# XMC4500 register map
Vendor: Infineon; File version: 1.2.0 (Reference Manual v1.2)
CPU: CM4 r2p0, little endian, MPU, FPU, 6 interrupt priority bits
Registers are 32-bit, read-write, reset 0x0 unless marked. A register's access mark holds for its fields unless they carry their own. Offsets are from the block's base; [hi:lo] are bit positions; {n}, {i} and the like mark numbered series; 'fields as' and 'values as' point back to an identical list.

## PPB — Cortex-M4 Private Peripheral Block
Base 0xE000E000
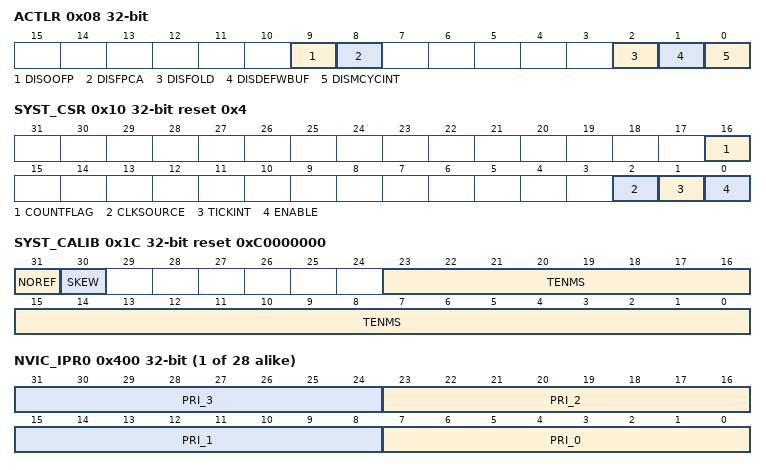
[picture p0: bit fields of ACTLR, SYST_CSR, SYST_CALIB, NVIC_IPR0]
0x08 ACTLR — Auxiliary Control Register
  [9] DISOOFP — Disable out of order FP execution
  [8] DISFPCA — Disable FPCA update
  [2] DISFOLD — Disable IT folding
  [1] DISDEFWBUF — Disable write buffer
  [0] DISMCYCINT — Disable load/store multiple
0x10 SYST_CSR reset 0x4 — SysTick Control and Status Register
  [16] COUNTFLAG — Counter Flag
  [2] CLKSOURCE — Indicates the clock source:
    0=external clock; 1=processor clock
  [1] TICKINT — Tick Interrupt Enable
    0=counting down to zero does not assert the SysTick exception request; 1=counting down to zero to asserts the SysTick exception request
  [0] ENABLE
    0=counter disabled; 1=counter enabled
0x14 SYST_RVR reset not defined — SysTick Reload Value Register
  [23:0] RELOAD — Reload Value
0x18 SYST_CVR reset not defined — SysTick Current Value Register
  [23:0] CURRENT — Current Value
0x1C SYST_CALIB reset 0xC0000000 — SysTick Calibration Value Register r
  [31] NOREF — No Reference Clock
    0=reference clock provided; 1=no reference clock provided
  [30] SKEW — Ten Milliseconds Skewed
    0=TENMS value is exact; 1=TENMS value is inexact, or not given
  [23:0] TENMS — Ten Milliseconds Reload Value
{0x100+4i} NVIC_ISER{i} (i=0..3) — Interrupt Set-enable Register {i}
  [31:0] SETENA — Interrupt set-enable bits
    0=interrupt disabled; 1=interrupt enabled
{0x180+4i} NVIC_ICER{i} (i=0..3) — Interrupt Clear-enable Register {i}
  [31:0] CLRENA — Interrupt clear-enable bits.
    0=interrupt disabled; 1=interrupt enabled
{0x200+4i} NVIC_ISPR{i} (i=0..3) — Interrupt Set-pending Register {i}
  [31:0] SETPEND — Interrupt set-pending bits.
    0=interrupt is not pending; 1=interrupt is pending
{0x280+4i} NVIC_ICPR{i} (i=0..3) — Interrupt Clear-pending Register {i}
  [31:0] CLRPEND — Interrupt set-pending bits.
    0=interrupt is not pending; 1=interrupt is pending
{0x300+4i} NVIC_IABR{i} (i=0..3) — Interrupt Active Bit Register {i}
  [31:0] ACTIVE — Interrupt active flags:
    0=interrupt not active; 1=interrupt active
{0x400+4i} NVIC_IPR{i} (i=0..27) — Interrupt Priority Register {i}
  [8n+7:8n] PRI_{n} (n=0..3) — Priority value {n}
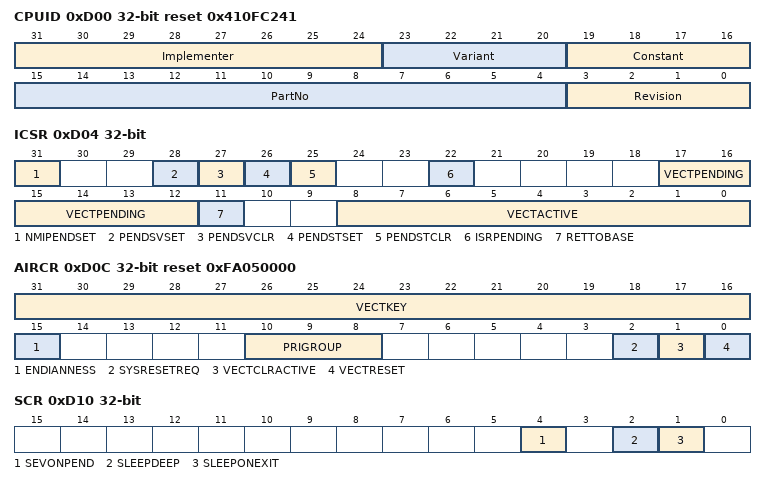
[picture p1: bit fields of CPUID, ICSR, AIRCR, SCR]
0xD00 CPUID ro reset 0x410FC241 — CPUID Base Register
  [31:24] Implementer — Implementer code
    65=ARM
  [23:20] Variant — Variant number
    0=Revision 0
  [19:16] Constant — Reads as 0xF
  [15:4] PartNo — Part number of the processor
    0xC24=Cortex-M4
  [3:0] Revision — Revision number
    1=Patch 1
0xD04 ICSR access per field — Interrupt Control and State Register
  [31] NMIPENDSET rw — NMI set-pending bit: 0b0=no effect, 0b1=changes NMI exception state to pending., 0b0=NMI exception is not pending, 0b1=NMI exception is pending.,
  [28] PENDSVSET rw — PendSV set-pending bit: 0b0=no effect, 0b1=changes PendSV exception state to pending., 0b0=PendSV exception is not pending, 0b1=PendSV exception is pending.,
  [27] PENDSVCLR wo — PendSV clear-pending bit
    0=no effect; 1=removes the pending state from the PendSV exception
  [26] PENDSTSET rw — SysTick exception set-pending bit
    0=no effect; 1=changes SysTick exception state to pending
  [25] PENDSTCLR wo — SysTick exception clear-pending bit
    0=no effect; 1=removes the pending state from the SysTick exception
  [22] ISRPENDING ro — Interrupt pending flag
    0=interrupt not pending; 1=interrupt pending
  [17:12] VECTPENDING ro — Vector Pending
    0=no pending exceptions
  [11] RETTOBASE ro — Return to Base
    0=there are preempted active exceptions to execute; 1=there are no active exceptions, or the currently-executing exception is the only active exception
  [8:0] VECTACTIVE ro — Active exception number
    0=Thread mode
0xD08 VTOR — Vector Table Offset Register
  [31:10] TBLOFF — Vector table base offset field
0xD0C AIRCR access per field reset 0xFA050000 — Application Interrupt and Reset Control Register
  [31:16] VECTKEY rw — Register key
  [15] ENDIANNESS ro — Data endianness bit
    0=Little-endian; 1=Big-endian
  [10:8] PRIGROUP rw — Interrupt priority grouping field
  [2] SYSRESETREQ wo — System reset request
    0=no system reset request; 1=asserts a signal to the outer system that requests a reset
  [1] VECTCLRACTIVE wo — Reserved for Debug use.
  [0] VECTRESET wo — Reserved for Debug use.
0xD10 SCR — System Control Register
  [4] SEVONPEND — Send Event on Pending bit:
    0=only enabled interrupts or events can wakeup the processor, disabled interrupts are excluded; 1=enabled events and all interrupts, including disabled interrupts, can wakeup the processor
  [2] SLEEPDEEP — Sleep or Deep Sleep
    0=sleep; 1=deep sleep
  [1] SLEEPONEXIT
    0=do not sleep when returning to Thread mode; 1=enter sleep, or deep sleep, on return from an ISR
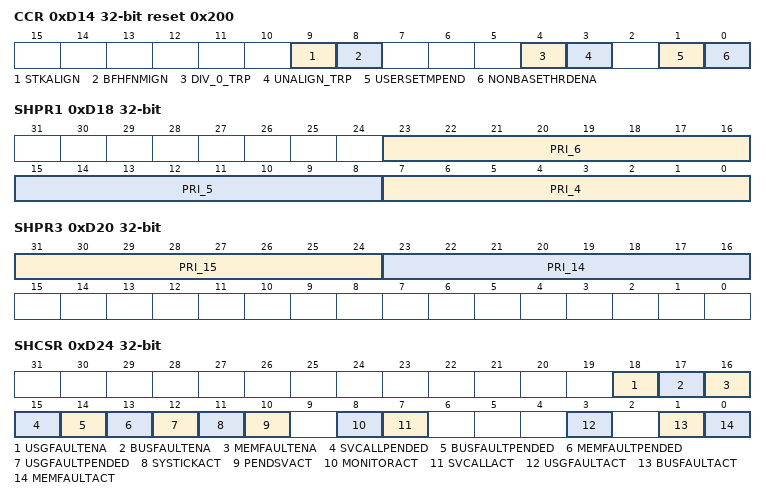
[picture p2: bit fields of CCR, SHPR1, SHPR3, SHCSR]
0xD14 CCR reset 0x200 — Configuration and Control Register
  [9] STKALIGN — Stack Alignment
    0=4-byte aligned; 1=8-byte aligned
  [8] BFHFNMIGN — Bus Fault Hard Fault and NMI Ignore
    0=data bus faults caused by load and store instructions cause a lock-up; 1=handlers running at priority -1 and -2 ignore data bus faults caused by load and store instructions
  [4] DIV_0_TRP — Divide by Zero Trap Enable
    0=do not trap divide by 0; 1=trap divide by 0
  [3] UNALIGN_TRP — Unaligned Access Trap Enable
    0=do not trap unaligned halfword and word accesses; 1=trap unaligned halfword and word accesses
  [1] USERSETMPEND — User Set Pending Enable
    0=disable; 1=enable
  [0] NONBASETHRDENA — Non Base Thread Mode Enable
    0=processor can enter Thread mode only when no exception is active; 1=processor can enter Thread mode from any level under the control of an EXC_RETURN value, see Exception returnException return occurs when the processor is in Handler mode and executes one of the following instructions to load the EXC_RETURN value into the PC:an LDM or POP instruction that loads the PCan LDR instruction with PC as the destinationa BX instruction using any register.EXC_RETURN is the value loaded into the LR on exception entry. The exception mechanism relies on this value to detect when the processor has completed an exception handler. The lowest five bits of this value provide information on the return stack and processor mode. shows the EXC_RETURN values with a description of the exception return behavior. All EXC_RETURN values have bits[31:5] set to one. When this value is loaded into the PC it indicates to the processor that the exception is complete, and the processor initiates the appropriate exception return sequence.Exception return behaviorEXC_RETURN[31:0]Description 0xFFFFFFF1 Return to Handler mode, exception return uses non-floating-point state from the MSP and execution uses MSP after return. 0xFFFFFFF9 Return to Thread mode, exception return uses non-floating-point state from MSP and execution uses MSP after return. 0xFFFFFFFD Return to Thread mode, exception return uses non-floating-point state from the PSP and execution uses PSP after return. 0xFFFFFFE1 Return to Handler mode, exception return uses floating-point-state from MSP and execution uses MSP after return. 0xFFFFFFE9 Return to Thread mode, exception return uses floating-point state from MSP and execution uses MSP after return. 0xFFFFFFED Return to Thread mode, exception return uses floating-point state from PSP and execution uses PSP after return. .
0xD18 SHPR1 — System Handler Priority Register 1
  [23:16] PRI_6 — Priority of system handler 6, UsageFault
  [15:8] PRI_5 — Priority of system handler 5, BusFault
  [7:0] PRI_4 — Priority of system handler 4, MemManage
0xD1C SHPR2 — System Handler Priority Register 2
  [31:24] PRI_11 — Priority of system handler 11, SVCall
0xD20 SHPR3 — System Handler Priority Register 3
  [31:24] PRI_15 — Priority of system handler 15
  [23:16] PRI_14 — Priority of system handler 14
0xD24 SHCSR — System Handler Control and State Register
  [18] USGFAULTENA — UsageFault enable bit
  [17] BUSFAULTENA — BusFault enable bit
  [16] MEMFAULTENA — MemManage enable bit
  [15] SVCALLPENDED — SVCall pending bit
  [14] BUSFAULTPENDED — BusFault exception pending bit
  [13] MEMFAULTPENDED — MemManage exception pending bit
  [12] USGFAULTPENDED — UsageFault exception pending bit
  [11] SYSTICKACT — SysTick exception active bit
  [10] PENDSVACT — PendSV exception active bit
  [8] MONITORACT — Debug monitor active bit
  [7] SVCALLACT — SVCall active bit
  [3] USGFAULTACT — UsageFault exception active bit
  [1] BUSFAULTACT — BusFault exception active bit
  [0] MEMFAULTACT — MemManage exception active bit
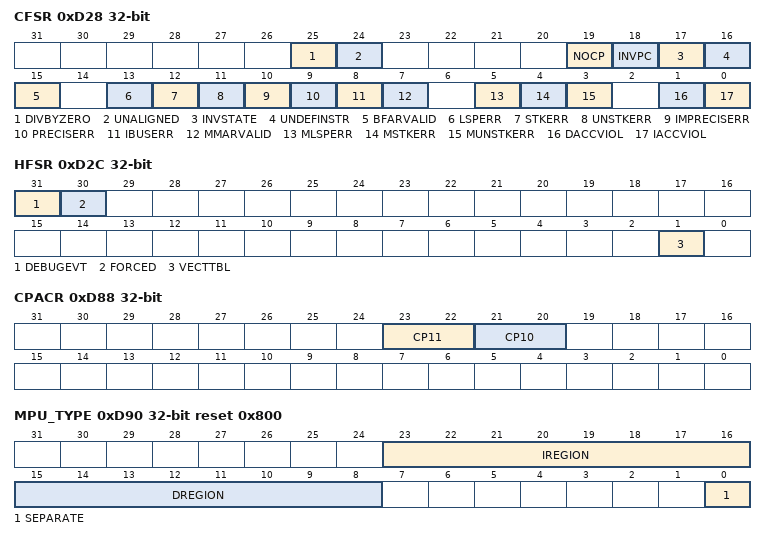
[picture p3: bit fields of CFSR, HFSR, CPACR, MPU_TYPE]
0xD28 CFSR — Configurable Fault Status Register
  [25] DIVBYZERO — Divide by zero UsageFault
    0=no divide by zero fault, or divide by zero trapping not enabled; 1=the processor has executed an SDIV or UDIV instruction with a divisor of 0
  [24] UNALIGNED — Unaligned access UsageFault
    0=no unaligned access fault, or unaligned access trapping not enabled; 1=the processor has made an unaligned memory access
  [19] NOCP — No coprocessor UsageFault
    0=no UsageFault caused by attempting to access a coprocessor; 1=the processor has attempted to access a coprocessor
  [18] INVPC — Invalid PC load UsageFault
    0=no invalid PC load UsageFault; 1=the processor has attempted an illegal load of EXC_RETURN to the PC, as a result of an invalid context, or an invalid EXC_RETURN value
  [17] INVSTATE — Invalid state UsageFault
    0=no invalid state UsageFault; 1=the processor has attempted to execute an instruction that makes illegal use of the EPSR
  [16] UNDEFINSTR — Undefined instruction UsageFault
    0=no undefined instruction UsageFault; 1=the processor has attempted to execute an undefined instruction
  [15] BFARVALID — BusFault Address Register (BFAR) valid flag
    0=value in BFAR is not a valid fault address; 1=BFAR holds a valid fault address
  [13] LSPERR — BusFault during floating point lazy state preservation
    0=No bus fault occurred during floating-point lazy state preservation; 1=A bus fault occurred during floating-point lazy state preservation
  [12] STKERR — BusFault on stacking for exception entry
    0=no stacking fault; 1=stacking for an exception entry has caused one or more BusFaults
  [11] UNSTKERR — BusFault on unstacking for a return from exception
    0=no unstacking fault; 1=stacking for an exception entry has caused one or more BusFaults
  [10] IMPRECISERR — Imprecise data bus error
    0=no imprecise data bus error; 1=a data bus error has occurred, but the return address in the stack frame is not related to the instruction that caused the error
  [9] PRECISERR — Precise data bus error
    0=no precise data bus error; 1=a data bus error has occurred, and the PC value stacked for the exception return points to the instruction that caused the fault
  [8] IBUSERR — Instruction bus error
    0=no instruction bus error; 1=instruction bus error
  [7] MMARVALID — MemManage Fault Address Register (MMFAR) valid flag
    0=value in MMAR is not a valid fault address; 1=MMAR holds a valid fault address
  [5] MLSPERR — MemManage fault during floating point lazy state preservation
    0=No MemManage fault occurred during floating-point lazy state preservation; 1=A MemManage fault occurred during floating-point lazy state preservation
  [4] MSTKERR — MemManage fault on stacking for exception entry
    0=no stacking fault; 1=stacking for an exception entry has caused one or more access violations
  [3] MUNSTKERR — MemManage fault on unstacking for a return from exception
    0=no unstacking fault; 1=unstack for an exception return has caused one or more access violations
  [1] DACCVIOL — Data access violation flag
    0=no data access violation fault; 1=the processor attempted a load or store at a location that does not permit the operation
  [0] IACCVIOL — Instruction access violation flag
    0=no instruction access violation fault; 1=the processor attempted an instruction fetch from a location that does not permit execution
0xD2C HFSR — HardFault Status Register
  [31] DEBUGEVT — Reserved for Debug use
  [30] FORCED — Forced HardFault
    0=no forced HardFault; 1=forced HardFault
  [1] VECTTBL — BusFault on vector table read
    0=no BusFault on vector table read; 1=BusFault on vector table read
0xD34 MMFAR reset not defined — MemManage Fault Address Register
  [31:0] ADDRESS — Address causing the fault
0xD38 BFAR reset not defined — BusFault Address Register
  [31:0] ADDRESS — Address causing the fault
0xD3C AFSR — Auxiliary Fault Status Register
  [31:0] VALUE — Reserved
0xD88 CPACR — Coprocessor Access Control Register
  [23:22] CP11 — Access privileges for coprocessor 11
    0=Access denied. Any attempted access generates a NOCP UsageFault.; 1=Privileged access only. An unprivileged access generates a NOCP fault.; 2=Reserved. The result of any access is Unpredictable.; 3=Full access
  [21:20] CP10 — Access privileges for coprocessor 10
    values as CP11
0xD90 MPU_TYPE ro reset 0x800
  [23:16] IREGION — Number of supported MPU instruction regions
  [15:8] DREGION — Number of supported MPU data regions
  [0] SEPARATE — Support for unified or separate instruction and date memory maps
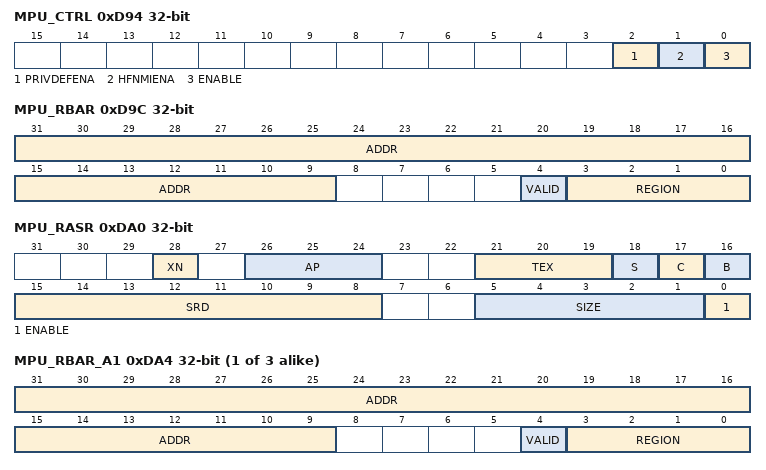
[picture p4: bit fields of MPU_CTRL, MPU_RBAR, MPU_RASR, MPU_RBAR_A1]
0xD94 MPU_CTRL — MPU Control Register
  [2] PRIVDEFENA — Enables privileged software access to the default memory map
    0=If the MPU is enabled, disables use of the default memory map. Any memory access to a location not covered by any enabled region causes a fault.; 1=If the MPU is enabled, enables use of the default memory map as a background region for privileged software accesses
  [1] HFNMIENA — Enable the operation of MPU during hard fault, NMI, and FAULTMASK handlers
    0=MPU is disabled during hard fault, NMI, and FAULTMASK handlers, regardless of the value of the ENABLE bit; 1=the MPU is enabled during hard fault, NMI, and FAULTMASK handlers
  [0] ENABLE — Enable MPU
    0=MPU disabled; 1=MPU enabled
0xD98 MPU_RNR — MPU Region Number Register
  [7:0] REGION
0xD9C MPU_RBAR — MPU Region Base Address Register
  [31:9] ADDR — Region base address field
  [4] VALID — MPU Region Number valid bit
    0=MPU_RNR not changed, and the processor: - updates the base address for the region specified in the MPU_RNR - ignores the value of the REGION field; 1=the processor: - updates the value of the MPU_RNR to the value of the REGION field - updates the base address for the region specified in the REGION field
  [3:0] REGION — MPU region field
0xDA0 MPU_RASR — MPU Region Attribute and Size Register
  [28] XN — Instruction access disable bit
    0=instruction fetches enabled; 1=instruction fetches disabled
  [26:24] AP — Access permission field
  [21:19] TEX — Memory access attribute
  [18] S — Shareable bit
  [17] C — Memory access attribute
  [16] B — Memory access attribute
  [15:8] SRD — Subregion disable bits
    0=corresponding sub-region is enabled; 1=corresponding sub-region is disabled
  [5:1] SIZE — MPU protection region size
  [0] ENABLE — Region enable bit.
{0xD9C+8i} MPU_RBAR_A{i} (i=1..3) — MPU Region Base Address Register A{i}
  fields as MPU_RBAR
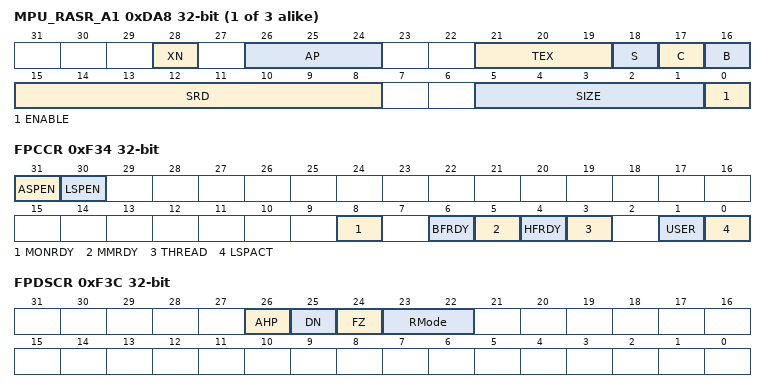
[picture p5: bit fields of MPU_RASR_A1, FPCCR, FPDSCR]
{0xDA0+8i} MPU_RASR_A{i} (i=1..3) — MPU Region Attribute and Size Register A{i}
  fields as MPU_RASR
0xF00 STIR wo — Software Trigger Interrupt Register
  [8:0] INTID — Interrupt ID of the interrupt to trigger
0xF34 FPCCR — Floating-point Context Control Register
  [31] ASPEN — Automatic State Preservation
    0=Disable CONTROL setting on execution of a floating-point instruction; 1=Enable CONTROL setting on execution of a floating-point instruction
  [30] LSPEN — Lazy State Preservation Enabled
    0=Disable automatic lazy state preservation for floating-point context; 1=Enable automatic lazy state preservation for floating-point context
  [8] MONRDY — Monitor Ready
    0=Debug Monitor is disabled or priority did not permit setting MON_PEND when the floating-point stack frame was allocated; 1=Debug Monitor is enabled and priority permits setting MON_PEND when the floating-point stack frame was allocated
  [6] BFRDY — BusFault Ready
    0=BusFault is disabled or priority did not permit setting the BusFault handler to the pending state when the floating-point stack frame was allocated; 1=BusFault is enabled and priority permitted setting the BusFault handler to the pending state when the floating-point stack frame was allocated
  [5] MMRDY — MemManage Ready
    0=MemManage is disabled or priority did not permit setting the MemManage handler to the pending state when the floating-point stack frame was allocated; 1=MemManage is enabled and priority permitted setting the MemManage handler to the pending state when the floating-point stack frame was allocated
  [4] HFRDY — HardFault Ready
    0=Priority did not permit setting the HardFault handler to the pending state when the floating-point stack frame was allocated; 1=Priority permitted setting the HardFault handler to the pending state when the floating-point stack frame was allocated
  [3] THREAD — Thread Mode allocated Stack Frame
    0=Mode was not Thread Mode when the floating-point stack frame was allocated; 1=Mode was Thread Mode when the floating-point stack frame was allocated
  [1] USER — User allocated Stack Frame
    0=Privilege level was not user when the floating-point stack frame was allocated; 1=Privilege level was user when the floating-point stack frame was allocated
  [0] LSPACT — Lazy State Preservation Active
    0=Lazy state preservation is not active; 1=Lazy state preservation is active. floating-point stack frame has been allocated but saving state to it has been deferred.
0xF38 FPCAR — Floating-point Context Address Register
  [31:3] ADDRESS
0xF3C FPDSCR — Floating-point Default Status Control Register
  [26] AHP — Default value for FPSCR.AHP
  [25] DN — Default value for FPSCR.DN
  [24] FZ — Default value for FPSCR.FZ
  [23:22] RMode — Default value for FPSCR.RMode
